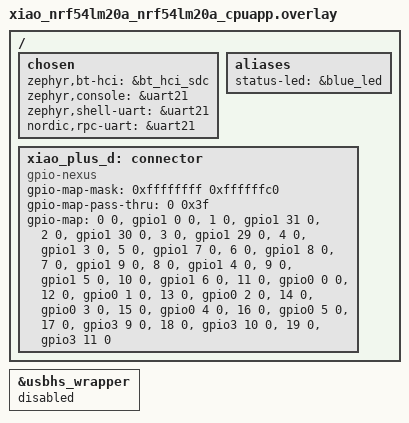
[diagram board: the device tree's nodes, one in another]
&usbhs_wrapper {
    status = "disabled";
};

/ {
    chosen {
        zephyr,bt-hci = &bt_hci_sdc;
        zephyr,console = &uart21;
        zephyr,shell-uart = &uart21;
        nordic,rpc-uart = &uart21;
    };
};

/ {
    aliases {
        status-led = &blue_led;
    };
};


/ {
    xiao_plus_d: connector {
        compatible = "gpio-nexus";
        #gpio-cells = <2>;
        gpio-map-mask = <0xffffffff 0xffffffc0>;
        gpio-map-pass-thru = <0 0x3f>;
        gpio-map = <0 0 &gpio1 0 0>, /* D0 */
            <1 0 &gpio1 31 0>,       /* D1 */
            <2 0 &gpio1 30 0>,       /* D2 */
            <3 0 &gpio1 29 0>,       /* D3 */
            <4 0 &gpio1 3 0>,        /* D4 */
            <5 0 &gpio1 7 0>,        /* D5 */
            <6 0 &gpio1 8 0>,        /* D6 */
            <7 0 &gpio1 9 0>,        /* D7 */
            <8 0 &gpio1 4 0>,        /* D8 */
            <9 0 &gpio1 5 0>,        /* D9 */
            <10 0 &gpio1 6 0>,       /* D10 */
            <11 0 &gpio0 0 0>,       /* D0.5 */
            <12 0 &gpio0 1 0>,       /* D1.5 */
            <13 0 &gpio0 2 0>,       /* D2.5 */
            <14 0 &gpio0 3 0>,       /* D3.5 */
            <15 0 &gpio0 4 0>,       /* D4.5 */
            <16 0 &gpio0 5 0>,       /* D5.5 */
            <17 0 &gpio3 9 0>,       /* D7.5 */
            <18 0 &gpio3 10 0>,      /* D8.5 */
            <19 0 &gpio3 11 0>;      /* D9.5 */
    };
};
